# K1921VG015 register map
Vendor: NIIET; Series: K1921Vxxx; File version: 1.14
Registers are 32-bit, read-write, reset 0x0 unless marked. A register's access mark holds for its fields unless they carry their own. Offsets are from the block's base; [hi:lo] are bit positions; lines under a group give offsets from that group; {n}, {i} and the like mark numbered series; 'fields as' and 'values as' point back to an identical list.

## RCU — Reset and clock unit registers
Base 0x3000E000
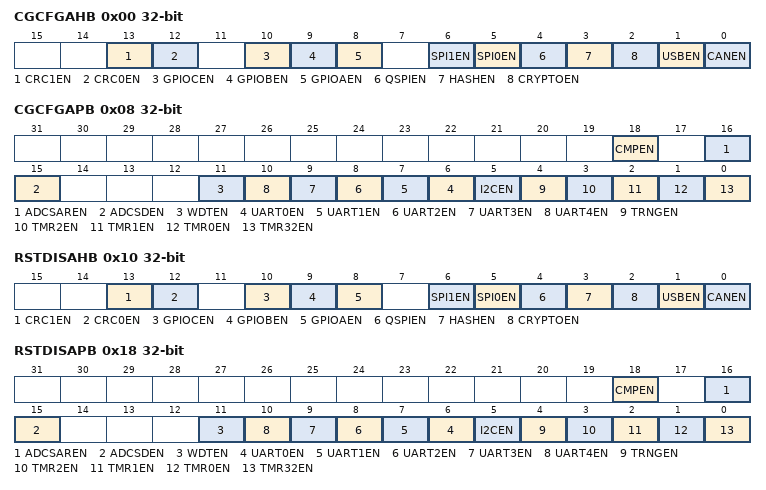
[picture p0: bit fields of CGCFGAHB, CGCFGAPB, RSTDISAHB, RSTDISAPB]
0x00 CGCFGAHB — Clockgate AHB configuration register
  [13] CRC1EN — Enable clock CRC1
  [12] CRC0EN — Enable clock CRC0
  [10] GPIOCEN — Enable clock GPIOC
  [9] GPIOBEN — Enable clock GPIOB
  [8] GPIOAEN — Enable clock GPIOA
  [6] SPI1EN — Enable clock SPI1
  [5] SPI0EN — Enable clock SPI0
  [4] QSPIEN — Enable clock QSPI
  [3] HASHEN — Enable clock HASH
  [2] CRYPTOEN — Enable clock CRYPTO
  [1] USBEN — Enable clock USB
  [0] CANEN — Enable clock CAN
0x08 CGCFGAPB — Clockgate APB configuration register
  [18] CMPEN — Enable clock CMP
  [16] ADCSAREN — Enable clock ADCSAR
  [15] ADCSDEN — Enable clock ADCSD
  [11] WDTEN — Enable clock WDT
  [n+6] UART{n}EN (n=0..4) — Enable clock UART{n}
  [5] I2CEN — Enable clock I2C
  [4] TRNGEN — Enable clock TRNG
  [3] TMR2EN — Enable clock TMR2
  [2] TMR1EN — Enable clock TMR1
  [1] TMR0EN — Enable clock TMR0
  [0] TMR32EN — Enable clock TMR32
0x10 RSTDISAHB — Reset disable AHB configuration register
  [13] CRC1EN — Disable reset from CRC1
  [12] CRC0EN — Disable reset from CRC0
  [10] GPIOCEN — Disable reset from GPIOC
  [9] GPIOBEN — Disable reset from GPIOB
  [8] GPIOAEN — Disable reset from GPIOA
  [6] SPI1EN — Disable reset from SPI1
  [5] SPI0EN — Disable reset from SPI0
  [4] QSPIEN — Disable reset from QSPI
  [3] HASHEN — Disable reset from HASH
  [2] CRYPTOEN — Disable reset from CRYPTO
  [1] USBEN — Disable reset from USB
  [0] CANEN — Disable reset from CAN
0x18 RSTDISAPB — Reset disable APB register
  [18] CMPEN — Disable reset from CMP
  [16] ADCSAREN — Disable reset from ADCSAR
  [15] ADCSDEN — Disable reset from ADCSD
  [11] WDTEN — Disable reset from WDT
  [n+6] UART{n}EN (n=0..4) — Disable reset from UART{n}
  [5] I2CEN — Disable reset from I2C
  [4] TRNGEN — Disable reset from TRNG
  [3] TMR2EN — Disable reset from TMR2
  [2] TMR1EN — Disable reset from TMR1
  [1] TMR0EN — Disable reset from TMR0
  [0] TMR32EN — Disable reset from TMR32
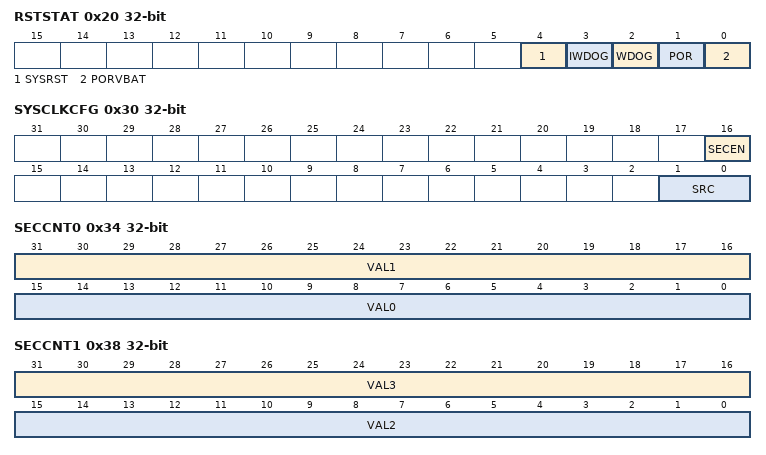
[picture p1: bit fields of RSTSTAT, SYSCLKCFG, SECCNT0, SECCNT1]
0x20 RSTSTAT — Reset Status Register
  [4] SYSRST
  [3] IWDOG — Lockup Reset Status
  [2] WDOG — System Reset Status
  [1] POR — WatchDog Reset status
  [0] PORVBAT — PowerOn Reset status
0x30 SYSCLKCFG — System clock configuration register
  [16] SECEN
  [1:0] SRC — System clock source
    0=REFCLK (HSI 1MHz if CPE=0 or HSE(XTALL) if CPE=1); 1=SRCCLK (HSE(XTALL) if CPE=0 or HSI 1MHz if CPE=1); 2=SYSPLL0CLK (Clock from PLL OUT[0]); 3=LSICLK (LSI (32768 Hz) from RTC)
0x34 SECCNT0 — Security counter configuration 0 register
  [31:16] VAL1, [15:0] VAL0
0x38 SECCNT1 — Security counter configuration 1 register
  [31:16] VAL3, [15:0] VAL2
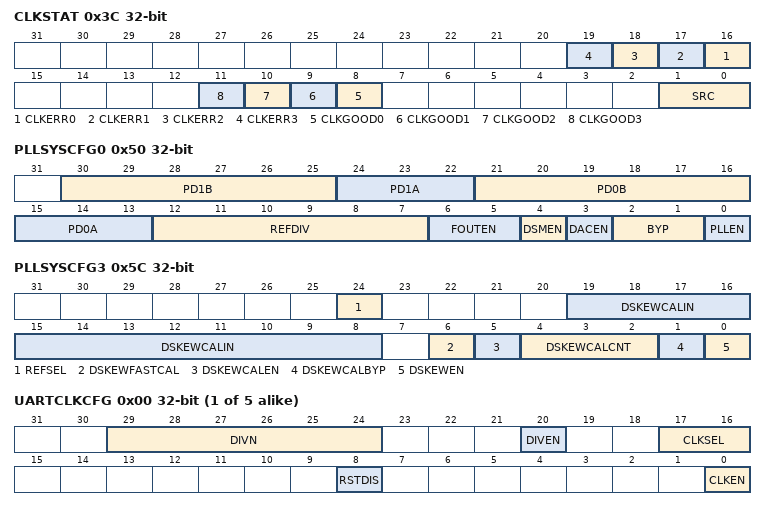
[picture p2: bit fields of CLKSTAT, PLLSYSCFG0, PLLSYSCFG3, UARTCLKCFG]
0x3C CLKSTAT ro — System clock status register
  [n+16] CLKERR{n} (n=0..3)
  [n+8] CLKGOOD{n} (n=0..3)
  [1:0] SRC — REFCLK:0:HSI 1MHz if CPE=0 or HSE(XTALL) if CPE=1;SRCCLK:1:HSE(XTALL) if CPE=0 or HSI 1MHz if CPE=1;SYSPLL0CLK:2: Clock from PLL OUT[0];LSICLK:3: LSI (32768 Hz) from RTC;
0x50 PLLSYSCFG0 — PLL configudration 0 register
  [30:25] PD1B
  [24:22] PD1A
  [21:16] PD0B
  [15:13] PD0A
  [12:7] REFDIV
  [6:5] FOUTEN — Output frequency enabled
  [4] DSMEN
  [3] DACEN
  [2:1] BYP — Bypass
  [0] PLLEN — PLL enable
0x54 PLLSYSCFG1 — PLL configudration 1 register
  [23:0] FRAC
0x58 PLLSYSCFG2 — PLL configudration 2 register
  [11:0] FBDIV
0x5C PLLSYSCFG3 — PLL configudration 3 register
  [24] REFSEL — 0-RefClk; 1- SrcClk
  [19:8] DSKEWCALIN
  [6] DSKEWFASTCAL
  [5] DSKEWCALEN
  [4:2] DSKEWCALCNT
  [1] DSKEWCALBYP
  [0] DSKEWEN — Bit must be 0
0x60 PLLSYSSTAT ro — PLL Status Register
  [0] LOCK — Lock status PLL
{0x70+4i} UARTCLKCFG[{i}] (i=0..4) group
  0x00 UARTCLKCFG — UART Clock and reset configuration register
    [29:24] DIVN — Divider coefficient
    [20] DIVEN — Divider enabled
    [17:16] CLKSEL — Clock select
      0=HSI (HSI 1MHz if CPE=0 or HSE(XTALL) if CPE=1); 1=HSE (HSE(XTALL) if CPE=0 or HSI 1MHz if CPE=1); 2=PLL0 (Clock from PLL OUT[0]); 3=PLL1 (Clock from PLL OUT[1])
    [8] RSTDIS — Reset disable
    [0] CLKEN — Clock enable
{0x94+4i} SPICLKCFG[{i}] (i=0..1) group
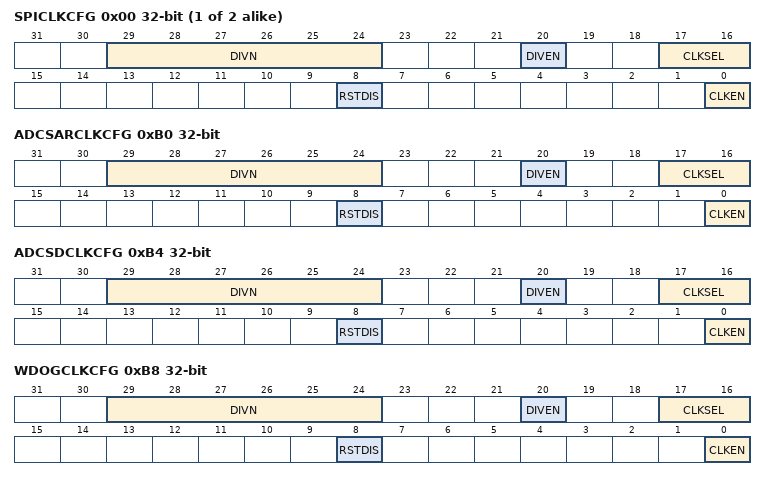
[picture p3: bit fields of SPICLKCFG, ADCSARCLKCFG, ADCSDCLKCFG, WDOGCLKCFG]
  0x00 SPICLKCFG — SPI Clock and Reset Configuration Register
    fields as UARTCLKCFG[0].UARTCLKCFG
0xB0 ADCSARCLKCFG — ADC SAR Configuraton Register
  fields as UARTCLKCFG[0].UARTCLKCFG
0xB4 ADCSDCLKCFG — ADC Sigma Delta Configuraton Register
  fields as UARTCLKCFG[0].UARTCLKCFG
0xB8 WDOGCLKCFG — Watchdog clock configuration register
  fields as UARTCLKCFG[0].UARTCLKCFG
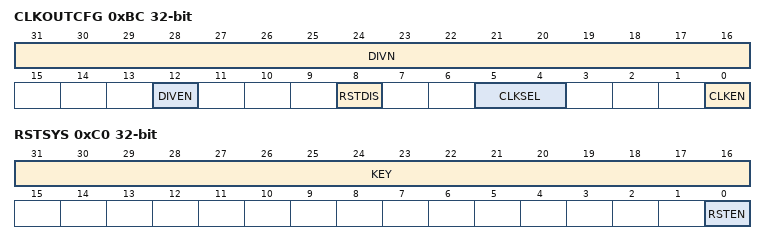
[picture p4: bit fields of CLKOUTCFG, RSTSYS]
0xBC CLKOUTCFG — Clockout configuration register
  [31:16] DIVN — Divider coefficient
  [12] DIVEN — Divider enabled
  [8] RSTDIS — Reset disable
  [5:4] CLKSEL — Clock select
    0=HSI (HSI 1MHz if CPE=0 or HSE(XTALL) if CPE=1); 1=HSE (HSE(XTALL) if CPE=0 or HSI 1MHz if CPE=1); 2=PLL0 (Clock from PLL OUT[0]); 3=LSI (Clock from RTC)
  [0] CLKEN — Clock enable
0xC0 RSTSYS wo — System Reset Register
  [31:16] KEY — KEY 'A55A' in hexadecimal for unblocking
  [0] RSTEN — Reset enable
